# SF32LB58x register map
File version: 1.0
CPU: CM33 r0p1, little endian, MPU, FPU, 3 interrupt priority bits
Registers are 32-bit, read-write, reset 0x0 unless marked. A register's access mark holds for its fields unless they carry their own. Offsets are from the block's base; [hi:lo] are bit positions; {n}, {i} and the like mark numbered series; 'fields as' and 'values as' point back to an identical list.

## LCDC1
Base 0x40008000
Same registers: LCDC2 0x5001C000
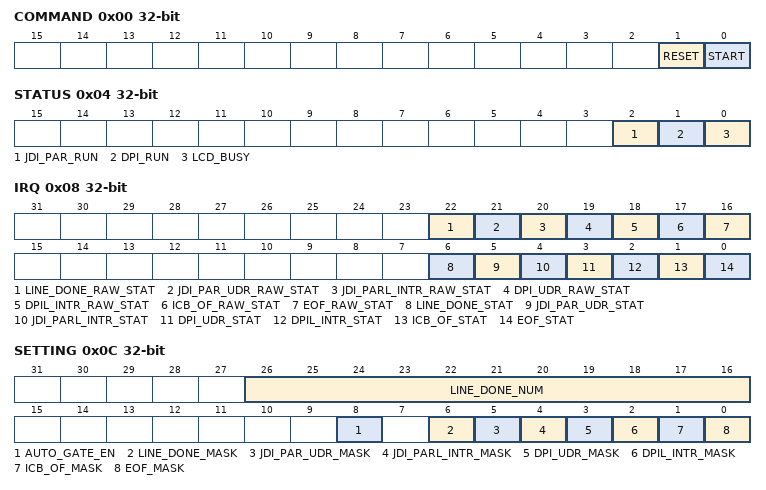
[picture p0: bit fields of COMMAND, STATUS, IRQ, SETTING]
0x00 COMMAND
  [1] RESET — 1: reset the whole graphics 0: release the reset
  [0] START — write 1 to trigger the lcd interface block
0x04 STATUS
  [2] JDI_PAR_RUN — JDI parallel interface is running
  [1] DPI_RUN — DPI interface is running
  [0] LCD_BUSY — LCS controll busy flag
0x08 IRQ
  [22] LINE_DONE_RAW_STAT — raw_status of line process done interrupt
  [21] JDI_PAR_UDR_RAW_STAT — raw_status of jdi parallel interface under run interrupt
  [20] JDI_PARL_INTR_RAW_STAT — raw_status of jdi parallel interface line interrupt
  [19] DPI_UDR_RAW_STAT — raw status of dpi under run interrupt
  [18] DPIL_INTR_RAW_STAT — raw status of dpi line interrupt
  [17] ICB_OF_RAW_STAT — raw status of icb overflow interrupt
  [16] EOF_RAW_STAT — raw status of end of frame interrupt
  [6] LINE_DONE_STAT — line process done interrupt, masked by mask register
  [5] JDI_PAR_UDR_STAT — jdi parallel interface under run interrupt, masked by mask register
  [4] JDI_PARL_INTR_STAT — jdi parallel interface line interrupt, masked by mask register
  [3] DPI_UDR_STAT — dpi under run interrupt, masked by mask register
  [2] DPIL_INTR_STAT — dpi line interrupt, masked by mask register
  [1] ICB_OF_STAT — icb overflow interrupt, masked by mask register
  [0] EOF_STAT — end of frame interrupt, masked by mask register
0x0C SETTING
  [26:16] LINE_DONE_NUM — line number of line process done interrupt
  [8] AUTO_GATE_EN — auto clock gating enable
  [6] LINE_DONE_MASK — line process done interrupt, 0: mask the interrupt
  [5] JDI_PAR_UDR_MASK — jdi parallel interface under run interrupt mask, 0: mask the interrupt
  [4] JDI_PARL_INTR_MASK — jdi parallel interface line interrupt, 0: mask the interrupt
  [3] DPI_UDR_MASK — dpi under run interrupt mask, 0: mask the interrupt
  [2] DPIL_INTR_MASK — dpi line interrupt, 0: mask the interrupt
  [1] ICB_OF_MASK — icb overflow interrupt mask, 0: mask the interrupt
  [0] EOF_MASK — end of frame interrupt mask, 0: mask the interrupt
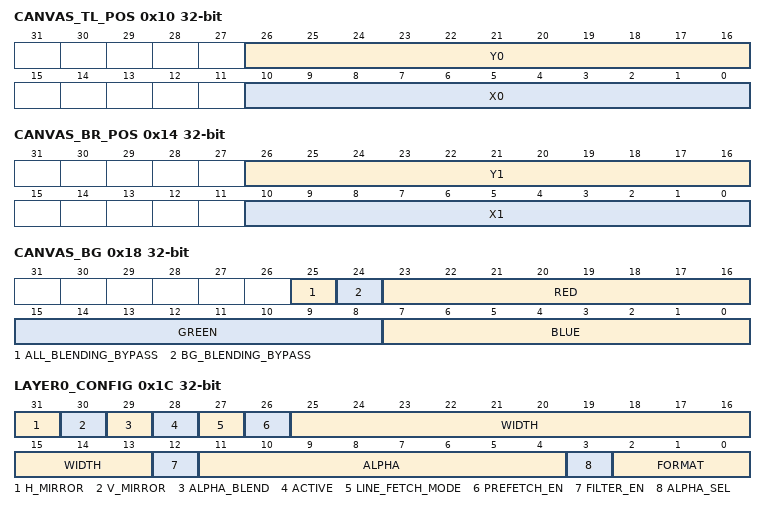
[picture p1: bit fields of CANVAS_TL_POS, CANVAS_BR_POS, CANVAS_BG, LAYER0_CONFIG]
0x10 CANVAS_TL_POS
  [26:16] Y0, [10:0] X0
0x14 CANVAS_BR_POS
  [26:16] Y1, [10:0] X1
0x18 CANVAS_BG
  [25] ALL_BLENDING_BYPASS — if this bit is set, epic is in pure dma mode. No blending operation.
  [24] BG_BLENDING_BYPASS — if this bit is set, the layer is not blending with background. The alpha value will be reserved to output.
  [23:16] RED — Red color
  [15:8] GREEN — green color
  [7:0] BLUE — blue color
0x1C LAYER0_CONFIG
  [31] H_MIRROR — set 1 to do horizontal mirror for the layer
  [30] V_MIRROR — set 1 to do vertical mirror for the layer
  [29] ALPHA_BLEND — set 1 to enable alpha blending mode. Use layer alpha as blending factor for image with Alpha. Alpha_out = Layer_alpha * Image_alpha
  [28] ACTIVE — layer active flag
  [27] LINE_FETCH_MODE — line fetch mode 0: address skip every single line 1: address skip every two line
  [26] PREFETCH_EN — preload 64 bytes extra data when reading pixel from memory
  [25:13] WIDTH — source image width(including padding), unit is bytes
  [12] FILTER_EN — layer color filter enable
  [11:4] ALPHA — layer alpha value
  [3] ALPHA_SEL — alpha selection 1'b0: select alpha according to image format 1'b1: select layer alpha
  [2:0] FORMAT — overlay layer input format 3'h0: RGB565 3'h1: RGB888 3'h2: ARGB8888 3'h3: ARGB8565 3'h4: RGB332 3'h5: A8 3'h6: L8 others: reserved
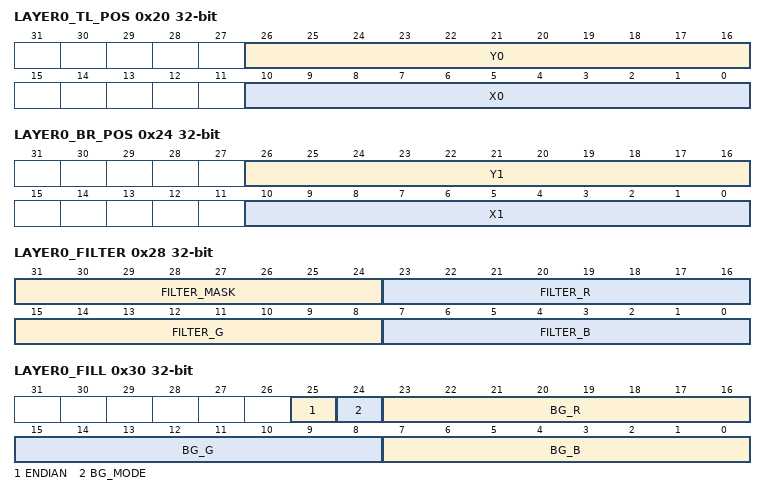
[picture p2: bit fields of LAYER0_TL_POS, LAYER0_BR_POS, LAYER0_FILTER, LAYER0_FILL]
0x20 LAYER0_TL_POS
  [26:16] Y0 — Coordingate Y-value
  [10:0] X0 — Coordinate X-value
0x24 LAYER0_BR_POS
  [26:16] Y1 — Coordingate Y-value
  [10:0] X1 — Coordinate X-value
0x28 LAYER0_FILTER
  [31:24] FILTER_MASK — layer color filter mask
  [23:16] FILTER_R — filter r color
  [15:8] FILTER_G — filter g color
  [7:0] FILTER_B — filter b color
0x2C LAYER0_SRC
  [31:0] ADDR — source image RGB data address[31:0]. For RGB565 format, address should be aligned to halfword. For ARGB8888 format, address should be aligned to word.
0x30 LAYER0_FILL
  [25] ENDIAN — input 565 data format endian 0: {R[4:0], G[5:3], G[2:0], B[4:0]} 1: {G[2:0], R[4:0], B[4:0], G[5:3]}
  [24] BG_MODE — line buffer bypass. Set 1 to bypass line buffer.
  [23:16] BG_R — background r color
  [15:8] BG_G — background g color
  [7:0] BG_B — background b color
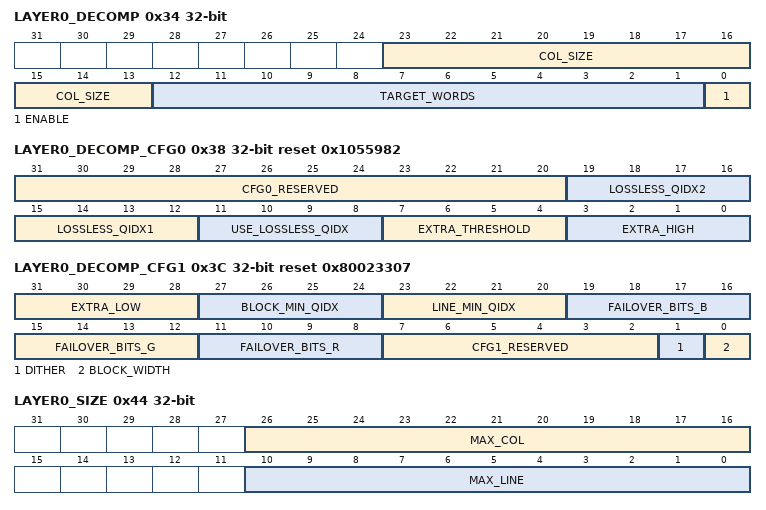
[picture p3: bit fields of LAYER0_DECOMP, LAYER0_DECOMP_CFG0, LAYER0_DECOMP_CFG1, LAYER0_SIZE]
0x34 LAYER0_DECOMP
  [23:13] COL_SIZE — number of colums in a line of original image, max column size is 1024
  [12:1] TARGET_WORDS — size of a single channel data before decompression. Unit is half word. Each line has 3 channels. So for each line, the compressed data size is target_words * 3 * 2 bytes.
  [0] ENABLE — decompression enable
0x38 LAYER0_DECOMP_CFG0 reset 0x1055982
  [31:20] CFG0_RESERVED
  [19:16] LOSSLESS_QIDX2 — condition to decrease qidx
  [15:12] LOSSLESS_QIDX1 — up level for adjusted qidx value for low quality block
  [11:8] USE_LOSSLESS_QIDX — condition to increase qidx
  [7:4] EXTRA_THRESHOLD — the threshold to distinguish high/low quality block
  [3:0] EXTRA_HIGH — extra bit for high quality bit
0x3C LAYER0_DECOMP_CFG1 reset 0x80023307
  [31:28] EXTRA_LOW — extra bit for low quality block
  [27:24] BLOCK_MIN_QIDX — minimum qidx for block mode
  [23:20] LINE_MIN_QIDX — minimum qidx for line mode
  [19:16] FAILOVER_BITS_B — failover compression mode target bits(Blue)
  [15:12] FAILOVER_BITS_G — failover compression mode target bits(Green)
  [11:8] FAILOVER_BITS_R — failover compression mode target bits(Red)
  [7:2] CFG1_RESERVED
  [1] DITHER — dithering function 0: off 1: on
  [0] BLOCK_WIDTH — block_size in pixel unit. 0: 16 pixels 1: 32 pixels Small block size will cause more blocks and more bits to store block information.
0x40 LAYER0_DECOMP_STAT
  [6:0] BUF_MAX_DEPTH — buf max usage
0x44 LAYER0_SIZE
  [26:16] MAX_COL — number of pixels of each line of source image(not including padding)
  [10:0] MAX_LINE — number of pixels of each column of source image(not including padding)
0x48 LAYER0_SCALE_H
  [25:0] PITCH — x-axis rescaling ration, 10.16 fixed point number, XPITCH lt MAX_COL/(X1-X0)
0x4C LAYER0_SCALE_V
  [25:0] PITCH — y-axis rescaling ratio, 10.16 fixed point number, YPITCH lt MAX_LINE/(Y1-Y0)
0x50 LAYER0_INIT_H
  [25:0] VAL — x-axis scale initial value, 10.16 format
0x54 LAYER0_INIT_V
  [25:0] VAL — y-axis scale initial value, 10.16 format
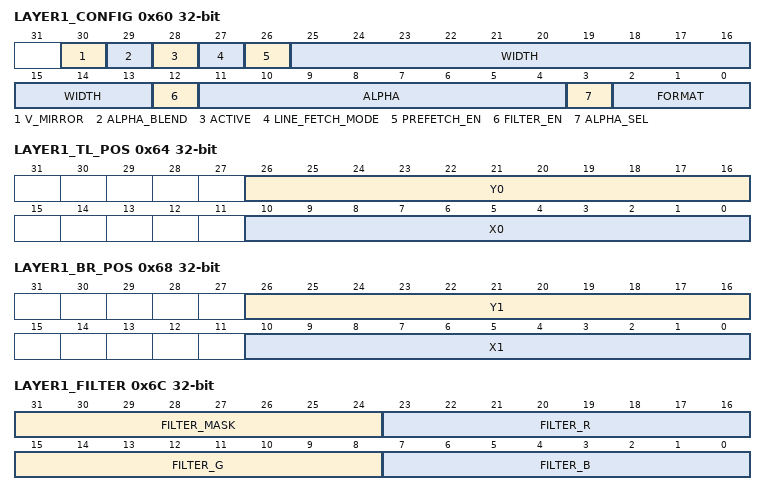
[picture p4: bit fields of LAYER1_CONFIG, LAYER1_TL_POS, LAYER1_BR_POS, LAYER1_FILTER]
0x60 LAYER1_CONFIG
  [30] V_MIRROR — set 1 to do vertical mirror for the layer
  [29] ALPHA_BLEND — set 1 to enable alpha blending mode. Use layer alpha as blending factor for image with Alpha. Alpha_out = Layer_alpha * Image_alpha
  [28] ACTIVE — layer active flag
  [27] LINE_FETCH_MODE — line fetch mode 0: address skip every single line 1: address skip every two line
  [26] PREFETCH_EN — preload 64 bytes extra data when reading pixel from memory
  [25:13] WIDTH — source image width(including padding), unit is bytes
  [12] FILTER_EN — layer color filter enable
  [11:4] ALPHA — layer alpha value
  [3] ALPHA_SEL — alpha selection 1'b0: select alpha according to image format 1'b1: select layer alpha
  [2:0] FORMAT — overlay layer input format 3'h0: RGB565 3'h1: RGB888 3'h2: ARGB8888 3'h3: ARGB8565 3'h4: RGB332 3'h5: A8 3'h6: L8 others: reserved
0x64 LAYER1_TL_POS
  [26:16] Y0 — Coordingate Y-value
  [10:0] X0 — Coordinate X-value
0x68 LAYER1_BR_POS
  [26:16] Y1 — Coordingate Y-value
  [10:0] X1 — Coordinate X-value
0x6C LAYER1_FILTER
  fields as LAYER0_FILTER
0x70 LAYER1_SRC
  fields as LAYER0_SRC
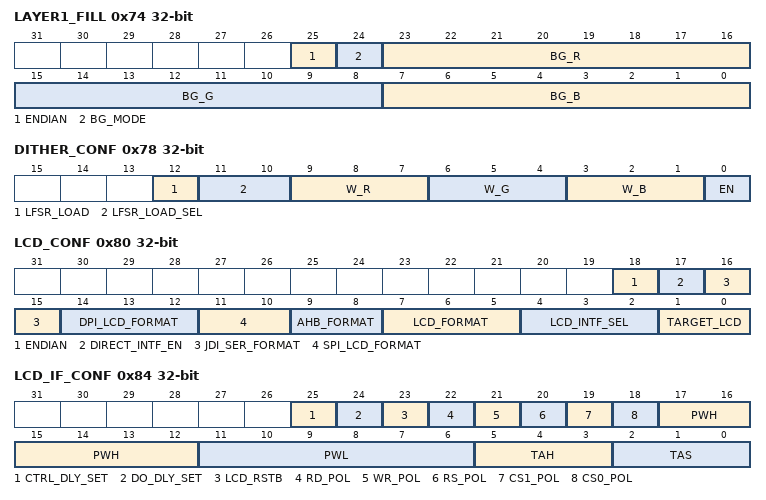
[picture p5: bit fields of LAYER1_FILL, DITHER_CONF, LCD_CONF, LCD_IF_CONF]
0x74 LAYER1_FILL
  [25] ENDIAN — input 565 data format endian 0: {R[4:0], G[5:3], G[2:0], B[4:0]} 1: {G[2:0], R[4:0], B[4:0], G[5:3]}
  [24] BG_MODE — not used
  [23:16] BG_R — background r color
  [15:8] BG_G — background g color
  [7:0] BG_B — background b color
0x78 DITHER_CONF
  [12] LFSR_LOAD — load lfsr init value
  [11:10] LFSR_LOAD_SEL — select lfsr 0: none 1: red 2: green 3: blue
  [9:7] W_R — red dither width
  [6:4] W_G — green dither width
  [3:1] W_B — blue dither width
  [0] EN — dither enable
0x7C DITHER_LFSR
  [31:0] INIT_VAL — lfsr init load value
0x80 LCD_CONF
  [18] ENDIAN — LCD 565 data format endian, this bit would affect SPI, DPI, DBI and AHB interface 565 format 0: {R[4:0], G[5:3], G[2:0], B[4:0]} 1: {G[2:0], R[4:0], B[4:0], G[5:3]}
  [17] DIRECT_INTF_EN — when the target LCD is AHB LCD, this bit enable the direct interface to DSI module. Direct interface has higher bandwidth and speed than AHB interface.
  [16:15] JDI_SER_FORMAT — JDI serial format 2'b00: 3-bit mode 2'b01: 4-bit mode 2'b10: 1-bit mode 2'b11: reserved
  [14:12] DPI_LCD_FORMAT — DPI LCD format 3'b000: 16-bit conf1 3'b001: 16-bit conf2 3'b010: 16-bit conf3 3'b011: 18-bit conf1 3'b100: 18-bit conf2 3'b101: 24-bit others: Reserved
  [11:10] SPI_LCD_FORMAT — SPI LCD format 2'b00: 8-bit RGB 3:3:2 2'b01: 16-bit RGB 5:6:5 2'b10: 24-bit RGB 8:8:8 2'b11: Reserved
  [9:8] AHB_FORMAT — AHB LCD/RAM output format: 0: RGB565 1: RGB888 2: ARGB8888 3: RGB332
  [7:5] LCD_FORMAT — LCD output format: 3'b000: 8-bit RGB 3:3:2 3'b001: 16-bit RGB 5:6:5 over 8-bit bus, 2 cycles/pixel 3'b010: 12-bit RGB 4:4:4 3'b011: 16-bit RGB 5:6:5 3'b100: 18-bit RGB 6:6:6 3'b101: 24-bit RGB 8:8:8 3'b110: 24-bit RGB 8:8:8 over 16-bit bus, 1.5 cycles/pixel 3'b111: 24-bit RGB 8:8:8 over 8-bit bus, 3cycles/pixel others: Reserved
  [4:2] LCD_INTF_SEL — 3'b000: 8080 DBI Type B 3'b001: SPI interface 3'b010: DBI to DSI interface 3'b011: DPI interface 3'b100: JDI serial interface 3'b101: JDI parallel interface 3'b110: 8080 DBI Type A 3'b111: DPI to DSI interface
  [1:0] TARGET_LCD — The Data can be sent to four destinations: 2'b00: LCD panel 0 2'b01: LCD panel 1 2'b10: AHB LCD 2'b11: AHB RAM
0x84 LCD_IF_CONF
  [25] CTRL_DLY_SET — if this bit is set to 1, LCD control output will be delayed for 1 lcdc clock cycle
  [24] DO_DLY_SET — if this bit is set to 1, LCD data output will be delayed for 1 lcdc clock cycle
  [23] LCD_RSTB — LCD RSTB pin, direct to output
  [22] RD_POL — LCD RD pin polarity. RD is 0 for write operation, 1 for idle if polarity bit is set as 0. RD bit definition is opposite if polarity bit is set as 1.
  [21] WR_POL — LCD WR pin polarity. WR is 0 for write operation, 1 for idle if polarity bit is set as 0. WR bit definition is opposite if polarity bit is set as 1.
  [20] RS_POL — LCD RS pin polarity. RS is 1 for data access, 0 for command access if polarity bit is set as 0. RS bit definition is opposite if polarity bit is set as 1.
  [19] CS1_POL — LCD0 CS pin polarity. CS is 0 for LCD chip select if polarity bit is set as 0. CS bit definition is opposite if polarity bit is set as 1.
  [18] CS0_POL — LCD1 CS pin polarity. CS is 0 for LCD chip select if polarity bit is set as 0. CS bit definition is opposite if polarity bit is set as 1.
  [17:12] PWH — inactive cycles of LCD_WR/LCD_RD for consecutive write/read operation
  [11:6] PWL — active cycles of LCD_WR/LCD_RD
  [5:3] TAH — hold cycles, delay from LCD_WR/LCD_RD inactive to LCD_CS inactive
  [2:0] TAS — setup cycles, delay from LCD_CS active to LCD_WR/LCD_RD active
0x88 LCD_MEM
  [31:0] ADDR — address for AHB LCD/AHB RAM
0x8C LCD_O_WIDTH
  [15:0] OFFSET — AHB RAM address offset for each line
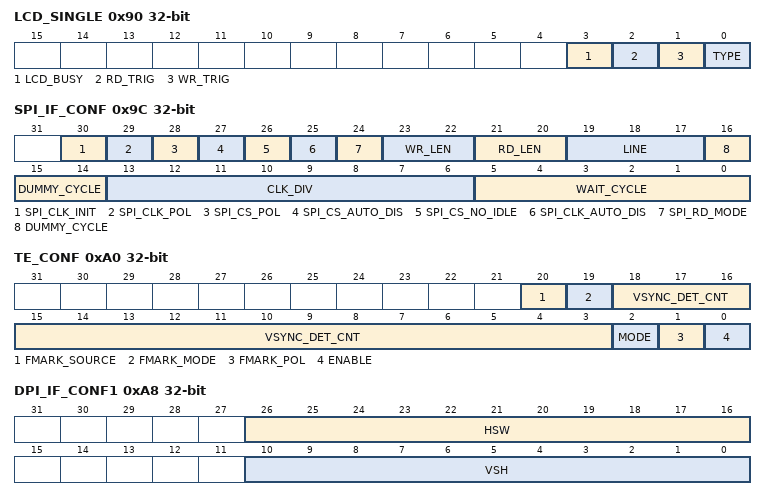
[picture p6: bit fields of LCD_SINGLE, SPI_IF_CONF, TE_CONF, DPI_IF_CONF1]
0x90 LCD_SINGLE
  [3] LCD_BUSY — LCD/SPI LCD interface is busy for single access
  [2] RD_TRIG — Single read operation trigger
  [1] WR_TRIG — Single write operation trigger
  [0] TYPE — LCD access type, this bit could affect all LCD interface including SPI, parellel and AHB 1'b0: command 1'b1: data
0x94 LCD_WR
  [31:0] DATA — LCD write data
0x98 LCD_RD
  [31:0] DATA — LCD read data
0x9C SPI_IF_CONF
  [30] SPI_CLK_INIT — SPI CLK idle state value 1'h0: high 1'h1: low
  [29] SPI_CLK_POL — SPI CLK polarity 1'h0: normal 1'h1: inverted
  [28] SPI_CS_POL — SPI CS polarity 0: low active 1: high active
  [27] SPI_CS_AUTO_DIS — 1: SPI CS is automatically disabled after data transaction 0: SPI CS is not disabled after data transaction
  [26] SPI_CS_NO_IDLE — 1: SPI CS is always active during data transaction 0: SPI CS is IDLE in wait state during data transaction
  [25] SPI_CLK_AUTO_DIS — 1: SPI clock auto disable in wait state during data transaction 0: SPI clock is always on in wait state during data transaction
  [24] SPI_RD_MODE — SPI read mode: 1'b0: normal read. Send write request before read. 1'b1: direct read. Read data without write request.
  [23:22] WR_LEN — SPI write data length(single access)
  [21:20] RD_LEN — SPI read data length(single access)
  [19:17] LINE — SPI line mode 0: 4-line 1: 4-line with 2 data line(support RGB565 and RGB888) 2: 4-line with 4 data line(support RGB565 and RGB888) 3: reserved 4: 3-line 5: 3-line with 2 data line(support RGB565 and RGB888) 6: 3-line with 4 data line(support RGB565 and RGB888) 7: reserved
  [16:14] DUMMY_CYCLE — SPI transaction dummy cycle
  [13:6] CLK_DIV — SPI clock divider
  [5:0] WAIT_CYCLE — SPI line wait cycle, wait cycle is after each line and is according to SPI clock. 0 refers to no wait cycle.
0xA0 TE_CONF
  [20] FMARK_SOURCE — TE signal source 1: use TE signal from DSI 0: use TE signal from external pin
  [19] FMARK_MODE — TE signal trigger mode 1: edge trigger 0: pulse trigger
  [18:3] VSYNC_DET_CNT — vsync signal detect counter, used for mode 1 to detect vsync signal
  [2] MODE — 0: vsync only TE mode 1: vsync+hsync TE mode
  [1] FMARK_POL — TE signal polarity
  [0] ENABLE — TE enable
0xA4 TE_CONF2
  [31:0] DLY_CNT — TE delay counter
0xA8 DPI_IF_CONF1
  [26:16] HSW — dpi hsync width
  [10:0] VSH — dpi vsync height
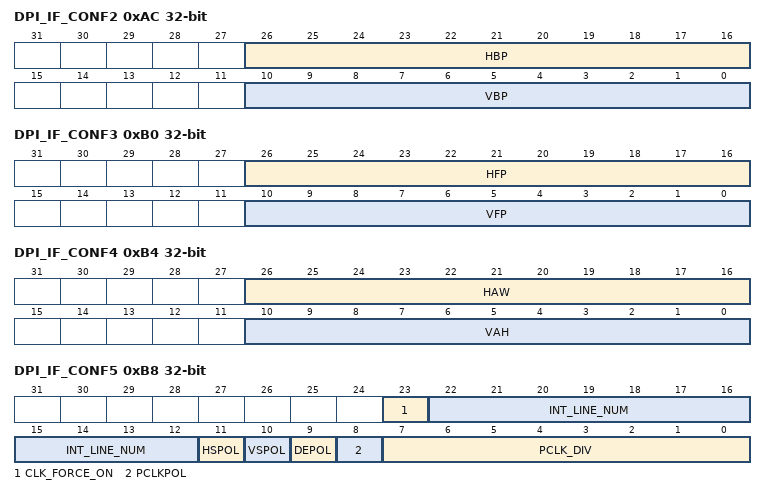
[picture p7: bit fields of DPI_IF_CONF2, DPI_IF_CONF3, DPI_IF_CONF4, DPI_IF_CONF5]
0xAC DPI_IF_CONF2
  [26:16] HBP — horizontal back porch
  [10:0] VBP — vertical back porch
0xB0 DPI_IF_CONF3
  [26:16] HFP — horizontal front porch
  [10:0] VFP — vertical front porch
0xB4 DPI_IF_CONF4
  [26:16] HAW — horizontal active width
  [10:0] VAH — vertical active height
0xB8 DPI_IF_CONF5
  [23] CLK_FORCE_ON — 1: force DPI clock on 0: DPI clock is controlled by hardware
  [22:12] INT_LINE_NUM — DPI interrupt line number
  [11] HSPOL — hsync polarity
  [10] VSPOL — vsync polarity
  [9] DEPOL — de polarity
  [8] PCLKPOL — pixel clock polarity
  [7:0] PCLK_DIV — pixel clock divider
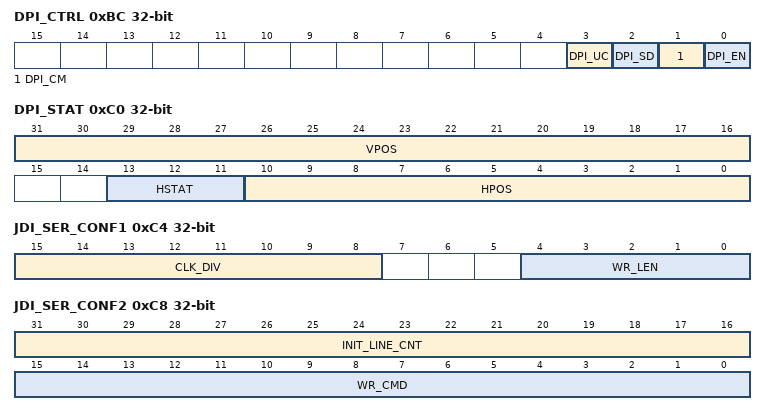
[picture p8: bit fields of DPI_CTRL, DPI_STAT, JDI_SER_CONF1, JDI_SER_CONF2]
0xBC DPI_CTRL
  [3] DPI_UC — dpi update config
  [2] DPI_SD — dpi shutdown
  [1] DPI_CM — dpi color mode
  [0] DPI_EN — dpi interface enable
0xC0 DPI_STAT
  [31:16] VPOS — dpi vertical position
  [13:11] HSTAT — horizontal status 0: idle 1: prep 2: hsync 3: hbp 4: hact 5: hfp 6: wait
  [10:0] HPOS — dpi horizontal position
0xC4 JDI_SER_CONF1
  [15:8] CLK_DIV — jdi serial clock divider
  [4:0] WR_LEN — jdi single write bit length
0xC8 JDI_SER_CONF2
  [31:16] INIT_LINE_CNT — jdi serial init line counter
  [15:0] WR_CMD — jdi serial data transfer write command
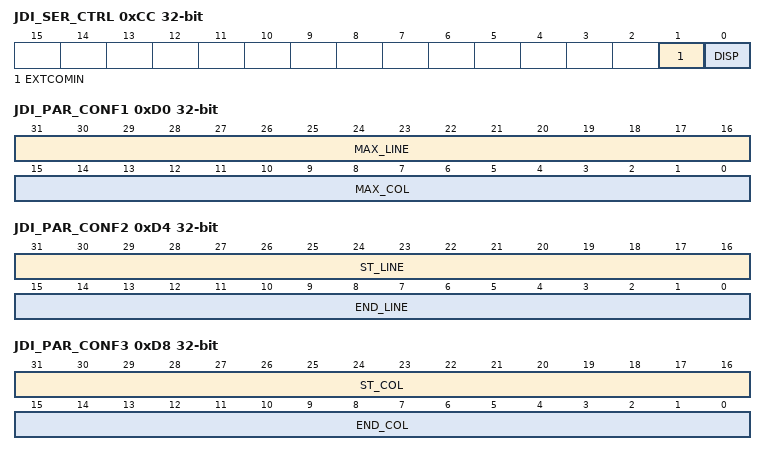
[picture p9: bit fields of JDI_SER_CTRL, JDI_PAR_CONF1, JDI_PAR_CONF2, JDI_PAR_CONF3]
0xCC JDI_SER_CTRL
  [1] EXTCOMIN — jdi serial interface extcomin control
  [0] DISP — jdi serial interface disp control
0xD0 JDI_PAR_CONF1
  [31:16] MAX_LINE — jdi parallel interface max line, line number start from 0
  [15:0] MAX_COL — jdi parallel interface max column, column number start from 0
0xD4 JDI_PAR_CONF2
  [31:16] ST_LINE — jdi parallel interface start line, line number start from 0
  [15:0] END_LINE — jdi parallel interface end line, line number start from 0
0xD8 JDI_PAR_CONF3
  [31:16] ST_COL — jdi parallel interface start column, column number start from 0
  [15:0] END_COL — jdi parallel interface end column, column number start from 0
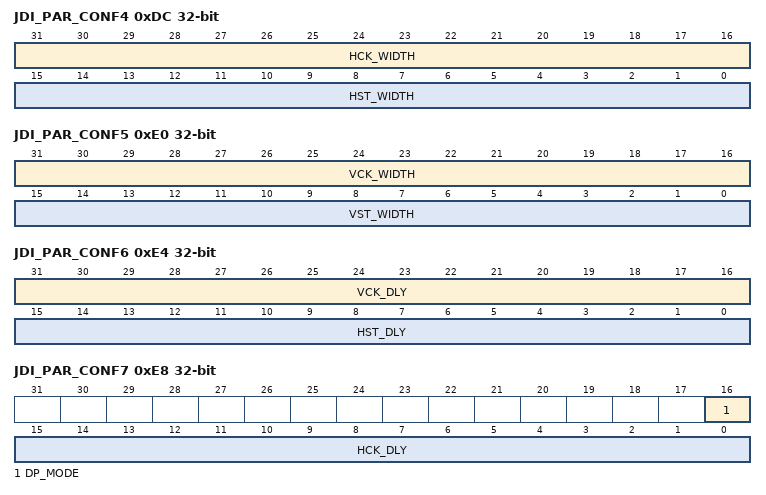
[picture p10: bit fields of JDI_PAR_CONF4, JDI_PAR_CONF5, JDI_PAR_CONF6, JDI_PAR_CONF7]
0xDC JDI_PAR_CONF4
  [31:16] HCK_WIDTH — jdi parallel interface HCK width, HSK width = lcd_ck_cycle * HCK_WIDTH
  [15:0] HST_WIDTH — jdi parallel interface HST width, HST width = lcd_ck_cycle * HST_WIDTH
0xE0 JDI_PAR_CONF5
  [31:16] VCK_WIDTH — jdi parallel interface VCK width, VCK width = lcd_ck_cycle * VCK_WIDTH
  [15:0] VST_WIDTH — jdi parallel interface VST width, VST width = lcd_ck_cycle * VST_WIDTH
0xE4 JDI_PAR_CONF6
  [31:16] VCK_DLY — jdi parallel interface VST to VCK delay, VST2VCK delay = lcd_ck_cycle * VCK_DLY
  [15:0] HST_DLY — jdi parallel interface VCK to HST delay, VCK2HST delay = lcd_ck_cycle * HST_DLY
0xE8 JDI_PAR_CONF7
  [16] DP_MODE — double pixel mode. Some jdi parallel screens use large pixel+small pixel structure. Set this bit to 1 to support this structure.
  [15:0] HCK_DLY — jdi parallel interface HST to HCK delay
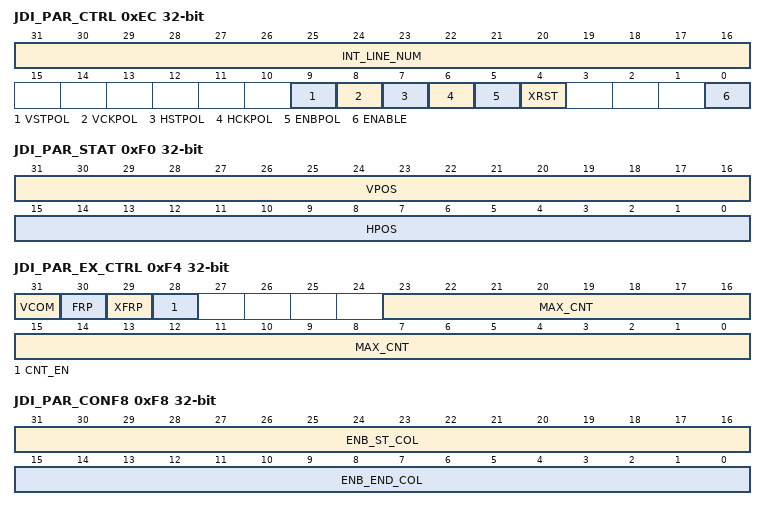
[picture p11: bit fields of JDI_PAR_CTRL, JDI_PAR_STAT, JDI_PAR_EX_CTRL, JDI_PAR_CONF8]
0xEC JDI_PAR_CTRL
  [31:16] INT_LINE_NUM — jdi parallel interface interrupt line number, line number start from 0.
  [9] VSTPOL — jdi parallel vst polarity
  [8] VCKPOL — jdi parallel vck polarity
  [7] HSTPOL — jdi parallel hst polarity
  [6] HCKPOL — jdi parallel hck polarity
  [5] ENBPOL — jdi parallel enb polarity
  [4] XRST — jdi parallel interface XRST
  [0] ENABLE — jdi parallel interface enable
0xF0 JDI_PAR_STAT
  [31:16] VPOS — jdi parallel vertical position
  [15:0] HPOS — jdi parallel horizontal position
0xF4 JDI_PAR_EX_CTRL
  [31] VCOM — VCOM value
  [30] FRP — FRP value
  [29] XFRP — XFRP value
  [28] CNT_EN — VCOM/FRP/XFRP counter enable
  [23:0] MAX_CNT — VCOM/FRP/XFRP max counter
0xF8 JDI_PAR_CONF8
  [31:16] ENB_ST_COL — jdi parallel interface enb start column, column number start from 0
  [15:0] ENB_END_COL — jdi parallel interface enb end column, column number start from 0
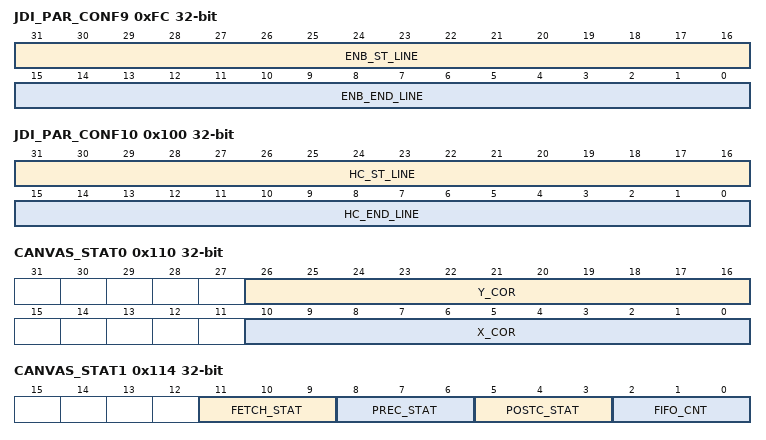
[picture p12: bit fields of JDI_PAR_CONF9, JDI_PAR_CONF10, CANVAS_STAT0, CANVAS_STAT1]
0xFC JDI_PAR_CONF9
  [31:16] ENB_ST_LINE — jdi parallel interface enb start line, line number start from 0
  [15:0] ENB_END_LINE — jdi parallel interface enb end line, line number start from 0
0x100 JDI_PAR_CONF10
  [31:16] HC_ST_LINE — jdi parallel interface horizontal control start line, line number start from 0
  [15:0] HC_END_LINE — jdi parallel interface horizontal control end line, line number start from 0
0x110 CANVAS_STAT0
  [26:16] Y_COR — canvas y cordinate
  [10:0] X_COR — canvas x cordinate
0x114 CANVAS_STAT1
  [11:9] FETCH_STAT — fetch status
  [8:6] PREC_STAT — prec status
  [5:3] POSTC_STAT — postc_status
  [2:0] FIFO_CNT — pre calc fifo count
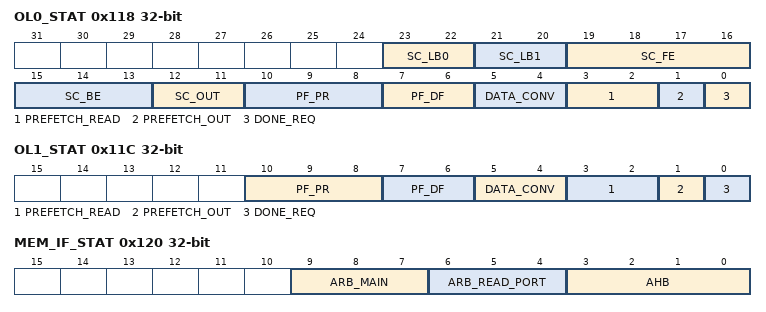
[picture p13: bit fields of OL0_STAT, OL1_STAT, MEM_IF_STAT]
0x118 OL0_STAT
  [23:22] SC_LB0, [21:20] SC_LB1, [19:16] SC_FE, [15:13] SC_BE, [12:11] SC_OUT, [10:8] PF_PR, [7:6] PF_DF, [5:4] DATA_CONV, [3:2] PREFETCH_READ, [1] PREFETCH_OUT, [0] DONE_REQ
0x11C OL1_STAT
  [10:8] PF_PR, [7:6] PF_DF, [5:4] DATA_CONV, [3:2] PREFETCH_READ, [1] PREFETCH_OUT, [0] DONE_REQ
0x120 MEM_IF_STAT
  [9:7] ARB_MAIN, [6:4] ARB_READ_PORT, [3:0] AHB
